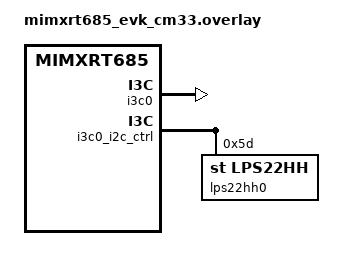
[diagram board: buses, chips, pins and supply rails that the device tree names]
&i3c0 {
	status = "okay";

	/*
	 * There might be other connected I2C devices
	 * (for example, if using Arduino shield) which
	 * cannot tolerate high clock speed. So slow
	 * down the clock.
	 */
	i2c-scl-hz = <400000>;
	i3c-scl-hz = <1000000>;
	i3c-od-scl-hz = <400000>;

	clk-divider = <8>;
	clk-divider-slow = <1>;
	clk-divider-tc = <1>;
};

&i3c0_i2c_ctrl {
	status = "okay";

	lps22hh0: lps22hh@5d {
		compatible = "st,lps22hh";
		reg = <0x5d>;

//		odr = <7>;

		status = "okay";
	};
};
